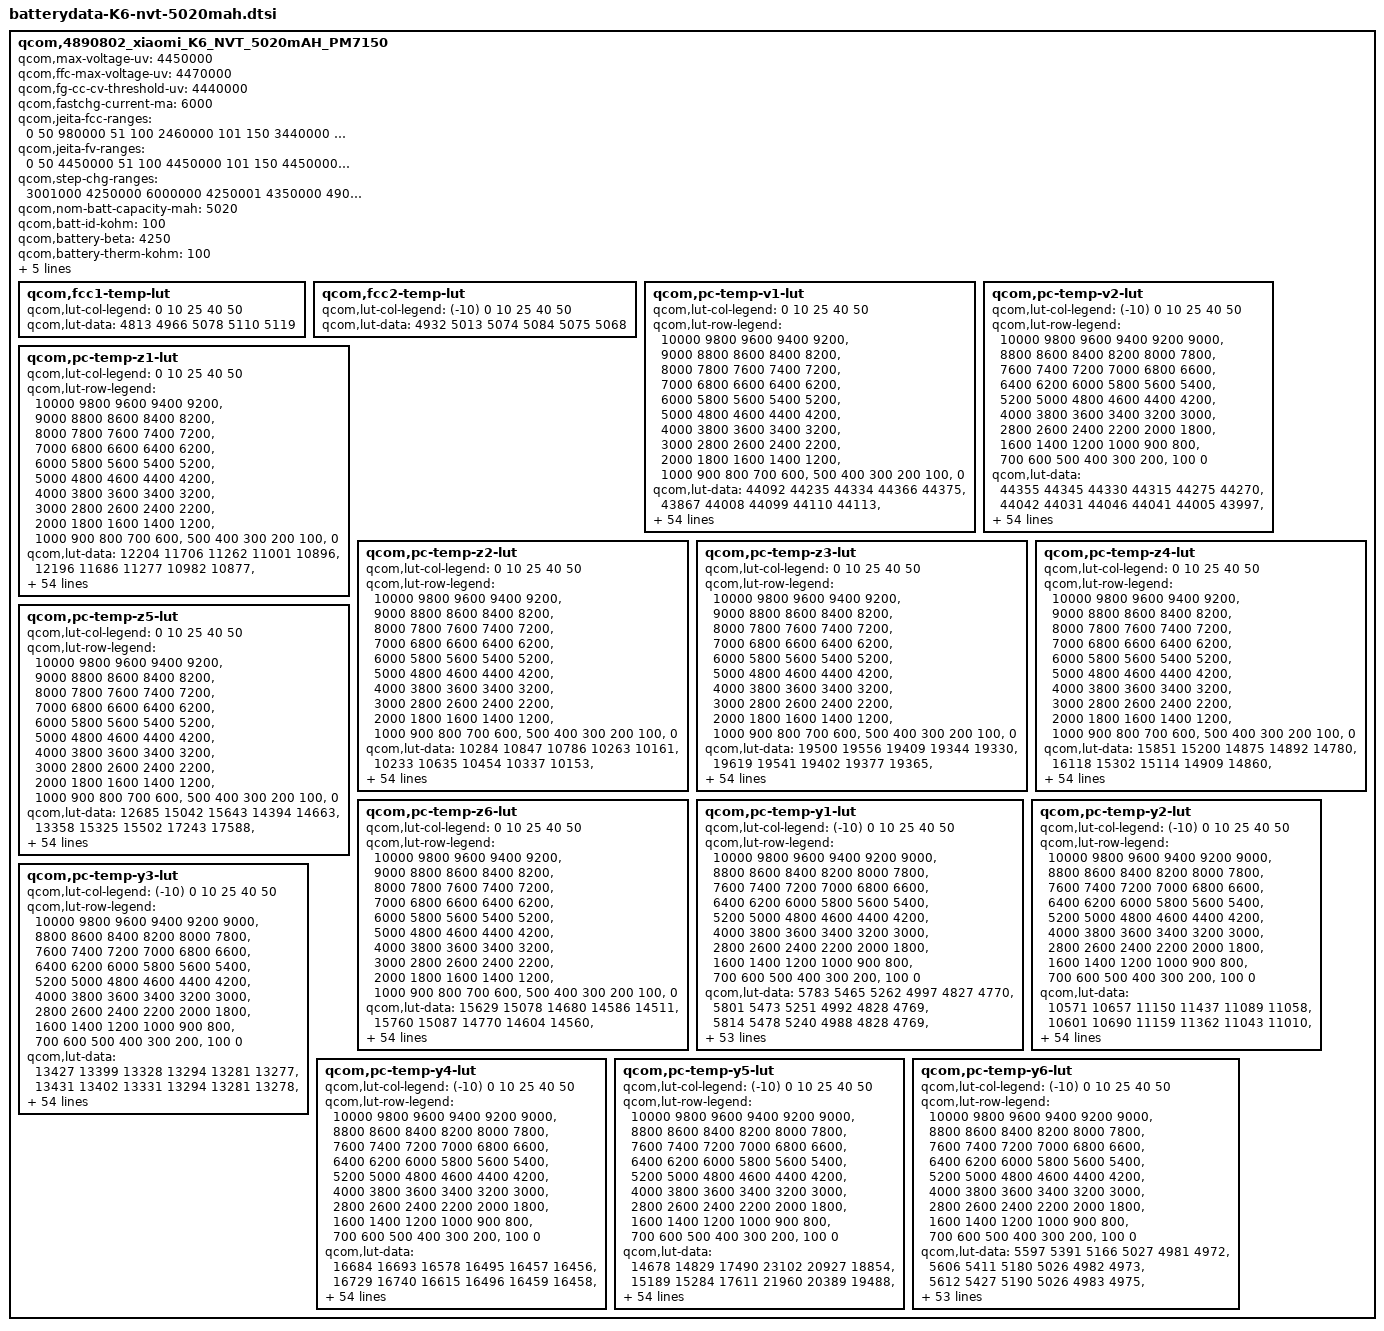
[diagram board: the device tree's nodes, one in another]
/*
 * Copyright (c) 2019, The Linux Foundation. All rights reserved.
 * Copyright (C) 2021 XiaoMi, Inc.
 *
 * This program is free software; you can redistribute it and/or modify
 * it under the terms of the GNU General Public License version 2 and
 * only version 2 as published by the Free Software Foundation.
 *
 * This program is distributed in the hope that it will be useful,
 * but WITHOUT ANY WARRANTY; without even the implied warranty of
 * MERCHANTABILITY or FITNESS FOR A PARTICULAR PURPOSE.  See the
 * GNU General Public License for more details.
 */

qcom,4890802_xiaomi_K6_NVT_5020mAH_PM7150 {
	/*K6_nvt_5020mAH_PM7150_averaged_MasterSlave_Sep20th2020 */
   	qcom,max-voltage-uv = <4450000>;
	qcom,ffc-max-voltage-uv = <4470000>;
	qcom,fg-cc-cv-threshold-uv = <4440000>;
	qcom,fastchg-current-ma = <6000>;
	qcom,jeita-fcc-ranges = <0  50   980000
				51  100  2460000
				101 150  3440000
				151 480  6000000
				481 600  2460000>;
	qcom,jeita-fv-ranges = <0   50  4450000
				51  100  4450000
				101 150  4450000
				151 480  4470000
				481 600  4100000>;
	qcom,step-chg-ranges = <3001000  4250000  6000000
				4250001  4350000  4900000
				4350001  4450000  4900000
				4450001  4460000  3900000
				4460001  4470000  3900000>;
	qcom,nom-batt-capacity-mah = <5020>;
	qcom,batt-id-kohm = <100>;
	qcom,battery-beta = <4250>;
	qcom,battery-therm-kohm = <100>;
	qcom,battery-type = "K6_nvt_5020mah";
	qcom,qg-batt-profile-ver = <100>;
	mi,six-pin-battery;
	mi,use-bq-pump;
	mi,step-chg-hysteresis = <5000>;

	qcom,fcc1-temp-lut {
		qcom,lut-col-legend = <0 10 25 40 50>;
		qcom,lut-data = <4813 4966 5078 5110 5119>;
	};

	qcom,fcc2-temp-lut {
		qcom,lut-col-legend = <(-10) 0 10 25 40 50>;
		qcom,lut-data = <4932 5013 5074 5084 5075 5068>;
	};

	qcom,pc-temp-v1-lut {
		qcom,lut-col-legend = <0 10 25 40 50>;
		qcom,lut-row-legend = <10000 9800 9600 9400 9200>,
			<9000 8800 8600 8400 8200>,
			<8000 7800 7600 7400 7200>,
			<7000 6800 6600 6400 6200>,
			<6000 5800 5600 5400 5200>,
			<5000 4800 4600 4400 4200>,
			<4000 3800 3600 3400 3200>,
			<3000 2800 2600 2400 2200>,
			<2000 1800 1600 1400 1200>,
			<1000 900 800 700 600>,
			<500 400 300 200 100>,
			<0>;
		qcom,lut-data = <44092 44235 44334 44366 44375>,
			<43867 44008 44099 44110 44113>,
			<43638 43781 43882 43894 43895>,
			<43406 43557 43666 43688 43693>,
			<43170 43333 43443 43472 43478>,
			<42930 43099 43216 43251 43257>,
			<42690 42857 42979 43021 43028>,
			<42449 42612 42733 42779 42791>,
			<42209 42368 42485 42531 42549>,
			<41975 42123 42238 42286 42305>,
			<41745 41885 41993 42042 42058>,
			<41521 41651 41753 41801 41816>,
			<41301 41423 41519 41563 41577>,
			<41088 41203 41290 41328 41343>,
			<40879 40988 41067 41103 41117>,
			<40674 40778 40851 40883 40897>,
			<40476 40572 40643 40673 40686>,
			<40283 40376 40443 40470 40482>,
			<40096 40197 40254 40277 40287>,
			<39925 40029 40087 40105 40111>,
			<39775 39856 39917 39938 39943>,
			<39629 39679 39688 39726 39736>,
			<39475 39489 39394 39435 39454>,
			<39316 39246 39165 39188 39207>,
			<39147 38968 39015 39038 39055>,
			<38943 38792 38895 38920 38934>,
			<38739 38703 38788 38801 38813>,
			<38608 38635 38694 38685 38694>,
			<38518 38559 38603 38580 38585>,
			<38449 38486 38508 38485 38488>,
			<38399 38419 38422 38401 38401>,
			<38359 38355 38352 38326 38321>,
			<38321 38297 38292 38259 38247>,
			<38286 38246 38235 38195 38178>,
			<38254 38201 38183 38135 38114>,
			<38223 38161 38133 38077 38051>,
			<38196 38128 38087 38019 37985>,
			<38162 38094 38043 37962 37917>,
			<38110 38039 37982 37891 37836>,
			<38040 37954 37892 37795 37733>,
			<37952 37854 37785 37686 37616>,
			<37830 37733 37670 37574 37497>,
			<37690 37592 37538 37447 37367>,
			<37529 37422 37373 37285 37199>,
			<37373 37267 37217 37138 37059>,
			<37238 37155 37107 37048 36986>,
			<37197 37119 37076 37016 36954>,
			<37173 37097 37052 36994 36933>,
			<37135 37075 37035 36975 36912>,
			<37102 37038 36997 36930 36859>,
			<37051 36871 36796 36701 36615>,
			<36839 36437 36365 36267 36183>,
			<36367 35850 35785 35691 35609>,
			<35725 35026 34987 34907 34828>,
			<34649 33597 33736 33689 33622>,
			<30000 30000 30000 30000 30000>;
	};

	qcom,pc-temp-v2-lut {
		qcom,lut-col-legend = <(-10) 0 10 25 40 50>;
		qcom,lut-row-legend = <10000 9800 9600 9400 9200 9000>,
			<8800 8600 8400 8200 8000 7800>,
			<7600 7400 7200 7000 6800 6600>,
			<6400 6200 6000 5800 5600 5400>,
			<5200 5000 4800 4600 4400 4200>,
			<4000 3800 3600 3400 3200 3000>,
			<2800 2600 2400 2200 2000 1800>,
			<1600 1400 1200 1000 900 800>,
			<700 600 500 400 300 200>,
			<100 0>;
		qcom,lut-data = <44355 44345 44330 44315 44275 44270>,
			<44042 44031 44046 44041 44005 43997>,
			<43757 43746 43781 43781 43749 43741>,
			<43506 43494 43539 43541 43513 43505>,
			<43290 43275 43320 43320 43295 43289>,
			<43075 43055 43096 43094 43072 43069>,
			<42844 42814 42854 42855 42835 42834>,
			<42605 42566 42606 42611 42593 42592>,
			<42364 42317 42357 42365 42349 42349>,
			<42117 42063 42107 42117 42102 42103>,
			<41871 41821 41860 41873 41858 41860>,
			<41633 41600 41619 41631 41619 41621>,
			<41399 41388 41383 41394 41383 41386>,
			<41159 41177 41151 41164 41153 41156>,
			<40914 40966 40926 40940 40928 40931>,
			<40664 40748 40713 40723 40712 40714>,
			<40399 40518 40523 40513 40504 40504>,
			<40124 40275 40331 40309 40304 40303>,
			<39875 40020 40107 40121 40118 40117>,
			<39661 39745 39855 39943 39940 39943>,
			<39463 39490 39610 39740 39745 39753>,
			<39272 39274 39366 39484 39512 39529>,
			<39092 39081 39141 39230 39277 39300>,
			<38921 38899 38954 39025 39068 39092>,
			<38761 38732 38792 38844 38874 38893>,
			<38608 38570 38644 38692 38717 38732>,
			<38455 38400 38508 38565 38591 38604>,
			<38298 38240 38384 38453 38482 38493>,
			<38177 38131 38274 38351 38379 38388>,
			<38097 38053 38173 38257 38284 38291>,
			<38035 37991 38077 38170 38199 38204>,
			<37974 37941 37981 38089 38124 38127>,
			<37917 37899 37902 38013 38052 38054>,
			<37860 37854 37852 37943 37983 37983>,
			<37804 37810 37814 37877 37916 37913>,
			<37748 37763 37773 37808 37837 37827>,
			<37688 37713 37732 37737 37742 37714>,
			<37625 37659 37685 37663 37644 37600>,
			<37555 37594 37625 37586 37553 37504>,
			<37478 37517 37552 37506 37462 37415>,
			<37392 37429 37462 37421 37371 37324>,
			<37304 37325 37343 37328 37281 37234>,
			<37214 37203 37202 37207 37163 37117>,
			<37126 37060 37035 37060 37016 36963>,
			<37043 36917 36876 36927 36898 36847>,
			<36964 36795 36775 36869 36852 36802>,
			<36921 36753 36741 36856 36843 36792>,
			<36874 36721 36707 36836 36830 36778>,
			<36825 36686 36658 36806 36806 36754>,
			<36775 36650 36561 36730 36741 36684>,
			<36718 36587 36342 36481 36468 36393>,
			<36628 36375 35879 35970 35978 35909>,
			<36444 35829 35213 35307 35336 35270>,
			<36058 34987 34182 34372 34446 34386>,
			<35309 33627 32498 32933 33098 33056>,
			<34358 32180 27628 27596 28297 29138>;
	};

	qcom,pc-temp-z1-lut {
		qcom,lut-col-legend = <0 10 25 40 50>;
		qcom,lut-row-legend = <10000 9800 9600 9400 9200>,
			<9000 8800 8600 8400 8200>,
			<8000 7800 7600 7400 7200>,
			<7000 6800 6600 6400 6200>,
			<6000 5800 5600 5400 5200>,
			<5000 4800 4600 4400 4200>,
			<4000 3800 3600 3400 3200>,
			<3000 2800 2600 2400 2200>,
			<2000 1800 1600 1400 1200>,
			<1000 900 800 700 600>,
			<500 400 300 200 100>,
			<0>;
		qcom,lut-data = <12204 11706 11262 11001 10896>,
			<12196 11686 11277 10982 10877>,
			<12184 11668 11252 10970 10870>,
			<12172 11653 11231 10960 10866>,
			<12159 11640 11222 10953 10861>,
			<12148 11629 11215 10946 10856>,
			<12140 11619 11205 10941 10852>,
			<12126 11609 11188 10935 10849>,
			<12109 11597 11176 10931 10847>,
			<12092 11585 11172 10929 10845>,
			<12070 11573 11170 10928 10844>,
			<12054 11559 11169 10927 10843>,
			<12045 11550 11169 10925 10843>,
			<12039 11555 11168 10924 10842>,
			<12033 11564 11167 10924 10843>,
			<12020 11567 11165 10924 10843>,
			<12009 11565 11165 10925 10843>,
			<12010 11564 11165 10925 10845>,
			<12013 11563 11165 10926 10846>,
			<12017 11562 11167 10928 10847>,
			<12045 11562 11170 10930 10848>,
			<12076 11567 11172 10930 10849>,
			<12073 11572 11174 10930 10851>,
			<12047 11574 11176 10930 10854>,
			<12028 11576 11177 10932 10855>,
			<12032 11579 11178 10937 10857>,
			<12041 11582 11182 10941 10859>,
			<12046 11587 11188 10945 10862>,
			<12078 11591 11192 10948 10865>,
			<12107 11597 11193 10951 10867>,
			<12096 11602 11195 10954 10870>,
			<12063 11606 11198 10957 10873>,
			<12055 11609 11204 10960 10876>,
			<12170 11613 11209 10963 10879>,
			<12308 11617 11212 10967 10883>,
			<12301 11621 11215 10971 10886>,
			<12175 11629 11220 10976 10890>,
			<12097 11638 11225 10979 10893>,
			<12107 11647 11231 10983 10896>,
			<12123 11657 11238 10988 10899>,
			<12136 11665 11245 10992 10902>,
			<12148 11672 11250 10995 10906>,
			<12160 11678 11255 10999 10909>,
			<12171 11687 11263 11002 10911>,
			<12194 11687 11270 11006 10914>,
			<12293 11695 11272 11010 10915>,
			<12420 11687 11276 11010 10915>,
			<12184 11694 11279 11009 10915>,
			<12192 11691 11271 11011 10917>,
			<12217 11704 11278 11017 10920>,
			<12236 11722 11294 11022 10925>,
			<12231 11727 11294 11030 10932>,
			<12236 11731 11311 11039 10940>,
			<12246 11787 11323 11053 10953>,
			<12246 11787 11323 11053 10953>,
			<12246 11787 11323 11053 10953>;
	};

	qcom,pc-temp-z2-lut {
		qcom,lut-col-legend = <0 10 25 40 50>;
		qcom,lut-row-legend = <10000 9800 9600 9400 9200>,
			<9000 8800 8600 8400 8200>,
			<8000 7800 7600 7400 7200>,
			<7000 6800 6600 6400 6200>,
			<6000 5800 5600 5400 5200>,
			<5000 4800 4600 4400 4200>,
			<4000 3800 3600 3400 3200>,
			<3000 2800 2600 2400 2200>,
			<2000 1800 1600 1400 1200>,
			<1000 900 800 700 600>,
			<500 400 300 200 100>,
			<0>;
		qcom,lut-data = <10284 10847 10786 10263 10161>,
			<10233 10635 10454 10337 10153>,
			<10288 10501 10514 10333 10154>,
			<10328 10461 10553 10331 10163>,
			<10318 10426 10526 10319 10161>,
			<10296 10391 10466 10284 10142>,
			<10287 10352 10417 10256 10128>,
			<10286 10326 10373 10206 10105>,
			<10285 10313 10349 10161 10078>,
			<10280 10302 10350 10158 10076>,
			<10267 10301 10352 10148 10080>,
			<10255 10315 10354 10140 10086>,
			<10246 10336 10356 10138 10097>,
			<10239 10355 10360 10136 10108>,
			<10239 10377 10374 10141 10118>,
			<10247 10398 10395 10156 10137>,
			<10258 10419 10409 10168 10146>,
			<10270 10439 10420 10179 10151>,
			<10285 10458 10431 10192 10156>,
			<10301 10476 10441 10205 10163>,
			<10318 10492 10453 10223 10178>,
			<10335 10513 10508 10281 10198>,
			<10354 10531 10649 10490 10239>,
			<10373 10546 10713 10627 10271>,
			<10391 10567 10602 10509 10280>,
			<10404 10573 10474 10323 10285>,
			<10416 10556 10464 10310 10283>,
			<10426 10538 10471 10407 10259>,
			<10437 10537 10483 10462 10225>,
			<10445 10538 10535 10400 10157>,
			<10448 10541 10583 10301 10086>,
			<10451 10549 10568 10241 10078>,
			<10454 10561 10520 10192 10090>,
			<10461 10569 10503 10176 10106>,
			<10470 10577 10517 10198 10129>,
			<10475 10584 10539 10235 10161>,
			<10478 10592 10558 10270 10210>,
			<10483 10601 10581 10310 10282>,
			<10494 10616 10613 10347 10334>,
			<10511 10637 10671 10387 10368>,
			<10528 10652 10713 10416 10388>,
			<10547 10658 10702 10426 10389>,
			<10571 10664 10681 10433 10385>,
			<10607 10676 10675 10449 10395>,
			<10882 10796 10701 10455 10400>,
			<10947 10853 10728 10472 10353>,
			<10888 10864 10706 10448 10341>,
			<10742 10939 10676 10450 10369>,
			<10689 11060 10669 10465 10388>,
			<10611 11173 10731 10534 10481>,
			<10241 11165 10724 10488 10377>,
			<10324 11112 10669 10361 10214>,
			<10381 10920 10650 10285 10149>,
			<10169 10591 10585 10235 10098>,
			<10169 10591 10585 10235 10098>,
			<10169 10591 10585 10235 10098>;
	};

	qcom,pc-temp-z3-lut {
		qcom,lut-col-legend = <0 10 25 40 50>;
		qcom,lut-row-legend = <10000 9800 9600 9400 9200>,
			<9000 8800 8600 8400 8200>,
			<8000 7800 7600 7400 7200>,
			<7000 6800 6600 6400 6200>,
			<6000 5800 5600 5400 5200>,
			<5000 4800 4600 4400 4200>,
			<4000 3800 3600 3400 3200>,
			<3000 2800 2600 2400 2200>,
			<2000 1800 1600 1400 1200>,
			<1000 900 800 700 600>,
			<500 400 300 200 100>,
			<0>;
		qcom,lut-data = <19500 19556 19409 19344 19330>,
			<19619 19541 19402 19377 19365>,
			<19696 19536 19428 19386 19375>,
			<19740 19550 19442 19391 19379>,
			<19755 19566 19444 19395 19384>,
			<19765 19569 19446 19398 19391>,
			<19766 19569 19447 19399 19393>,
			<19759 19568 19448 19401 19392>,
			<19749 19565 19449 19403 19390>,
			<19742 19559 19445 19402 19389>,
			<19736 19552 19438 19396 19388>,
			<19730 19543 19432 19392 19387>,
			<19723 19533 19427 19390 19386>,
			<19717 19526 19423 19389 19383>,
			<19711 19519 19419 19387 19381>,
			<19703 19514 19416 19385 19377>,
			<19693 19511 19414 19383 19374>,
			<19679 19507 19411 19381 19371>,
			<19662 19501 19409 19378 19368>,
			<19651 19494 19404 19372 19364>,
			<19645 19492 19400 19365 19358>,
			<19641 19495 19405 19365 19358>,
			<19641 19500 19424 19378 19363>,
			<19643 19505 19433 19387 19368>,
			<19646 19512 19416 19377 19368>,
			<19653 19514 19396 19360 19367>,
			<19662 19504 19395 19364 19370>,
			<19664 19495 19398 19396 19391>,
			<19660 19494 19403 19415 19404>,
			<19654 19495 19420 19411 19399>,
			<19649 19497 19436 19405 19391>,
			<19642 19501 19435 19397 19384>,
			<19637 19506 19428 19389 19379>,
			<19633 19506 19423 19381 19372>,
			<19629 19505 19418 19375 19363>,
			<19625 19504 19414 19370 19354>,
			<19621 19500 19409 19365 19349>,
			<19617 19495 19404 19359 19345>,
			<19612 19490 19401 19358 19344>,
			<19607 19486 19400 19359 19344>,
			<19601 19481 19399 19360 19344>,
			<19592 19478 19396 19359 19347>,
			<19583 19473 19392 19358 19352>,
			<19573 19466 19388 19359 19356>,
			<19498 19440 19380 19359 19356>,
			<19477 19422 19372 19347 19344>,
			<19432 19419 19368 19343 19343>,
			<19308 19391 19364 19340 19331>,
			<19303 19333 19353 19333 19327>,
			<19295 19333 19347 19330 19322>,
			<19273 19331 19352 19342 19333>,
			<19288 19326 19356 19357 19347>,
			<19305 19321 19351 19358 19349>,
			<19326 19346 19350 19353 19350>,
			<19326 19346 19350 19353 19350>,
			<19326 19346 19350 19353 19350>;
	};

	qcom,pc-temp-z4-lut {
		qcom,lut-col-legend = <0 10 25 40 50>;
		qcom,lut-row-legend = <10000 9800 9600 9400 9200>,
			<9000 8800 8600 8400 8200>,
			<8000 7800 7600 7400 7200>,
			<7000 6800 6600 6400 6200>,
			<6000 5800 5600 5400 5200>,
			<5000 4800 4600 4400 4200>,
			<4000 3800 3600 3400 3200>,
			<3000 2800 2600 2400 2200>,
			<2000 1800 1600 1400 1200>,
			<1000 900 800 700 600>,
			<500 400 300 200 100>,
			<0>;
		qcom,lut-data = <15851 15200 14875 14892 14780>,
			<16118 15302 15114 14909 14860>,
			<15930 15325 15038 14882 14845>,
			<15709 15240 14952 14836 14811>,
			<15541 15106 14899 14806 14787>,
			<15385 15013 14854 14782 14767>,
			<15264 14948 14818 14762 14750>,
			<15170 14897 14787 14740 14732>,
			<15092 14857 14763 14723 14718>,
			<15026 14825 14746 14715 14711>,
			<14970 14799 14732 14710 14707>,
			<14923 14775 14724 14706 14704>,
			<14883 14758 14720 14701 14701>,
			<14850 14750 14716 14697 14697>,
			<14821 14745 14711 14692 14694>,
			<14792 14741 14706 14687 14691>,
			<14777 14738 14702 14683 14688>,
			<14778 14736 14699 14679 14685>,
			<14784 14730 14695 14676 14682>,
			<14785 14722 14691 14672 14676>,
			<14770 14719 14688 14669 14670>,
			<14753 14721 14701 14676 14676>,
			<14751 14726 14756 14734 14737>,
			<14752 14758 14796 14780 14784>,
			<14753 14830 14817 14787 14779>,
			<14786 14858 14829 14791 14766>,
			<14835 14847 14824 14782 14747>,
			<14847 14830 14801 14733 14714>,
			<14847 14815 14777 14700 14692>,
			<14846 14799 14750 14695 14688>,
			<14841 14784 14728 14691 14685>,
			<14827 14769 14720 14689 14681>,
			<14814 14757 14716 14686 14677>,
			<14803 14750 14714 14684 14674>,
			<14792 14745 14713 14682 14671>,
			<14780 14741 14712 14681 14670>,
			<14768 14736 14711 14681 14670>,
			<14757 14732 14709 14682 14670>,
			<14745 14729 14709 14684 14671>,
			<14734 14727 14711 14691 14683>,
			<14728 14725 14714 14698 14694>,
			<14724 14716 14709 14695 14690>,
			<14717 14705 14699 14689 14681>,
			<14700 14698 14694 14687 14686>,
			<14695 14679 14679 14679 14681>,
			<14696 14668 14660 14661 14657>,
			<14743 14664 14656 14658 14651>,
			<14878 14683 14649 14649 14647>,
			<14880 14741 14646 14637 14633>,
			<14884 14733 14643 14628 14624>,
			<14901 14737 14651 14647 14654>,
			<14883 14758 14661 14651 14661>,
			<14888 14770 14668 14654 14667>,
			<14891 14757 14672 14661 14667>,
			<14891 14757 14672 14661 14667>,
			<14891 14757 14672 14661 14667>;
	};

	qcom,pc-temp-z5-lut {
		qcom,lut-col-legend = <0 10 25 40 50>;
		qcom,lut-row-legend = <10000 9800 9600 9400 9200>,
			<9000 8800 8600 8400 8200>,
			<8000 7800 7600 7400 7200>,
			<7000 6800 6600 6400 6200>,
			<6000 5800 5600 5400 5200>,
			<5000 4800 4600 4400 4200>,
			<4000 3800 3600 3400 3200>,
			<3000 2800 2600 2400 2200>,
			<2000 1800 1600 1400 1200>,
			<1000 900 800 700 600>,
			<500 400 300 200 100>,
			<0>;
		qcom,lut-data = <12685 15042 15643 14394 14663>,
			<13358 15325 15502 17243 17588>,
			<14059 15683 16925 18187 19154>,
			<14693 16190 17909 19103 20068>,
			<15190 16877 18378 19737 21230>,
			<15623 17514 18706 20171 22540>,
			<16058 18072 19249 20691 23700>,
			<16510 18666 20157 22038 24628>,
			<17018 19361 21051 23495 25465>,
			<17643 20136 21834 23772 26310>,
			<18392 20998 22498 23631 27152>,
			<19234 22044 22704 23798 27987>,
			<20212 22927 22680 24603 28953>,
			<21402 23450 22723 25569 29848>,
			<23006 23881 23114 26421 30512>,
			<25565 24432 23769 27447 31109>,
			<27204 25466 24473 28506 31437>,
			<26656 26251 25316 29937 32731>,
			<25308 26274 26102 30818 33901>,
			<24811 26121 26610 30155 34233>,
			<25743 26442 27217 28898 34826>,
			<27533 31175 31183 29414 34985>,
			<30390 36565 42650 34734 34887>,
			<35648 38665 47789 38404 34684>,
			<41327 40215 36446 31156 29594>,
			<48076 40331 22897 19637 20920>,
			<54210 34389 20818 18784 20289>,
			<54958 28097 20273 24922 26973>,
			<51047 27428 20353 29385 31623>,
			<46370 27325 25290 30798 32192>,
			<42919 27372 31003 31630 32427>,
			<39778 29614 32461 31440 32559>,
			<38104 33034 33139 30424 32938>,
			<37276 35758 34031 29959 32872>,
			<36785 38410 35602 30594 31011>,
			<36672 39544 36718 31282 29007>,
			<36668 39589 36504 31065 28816>,
			<36744 39474 35872 30329 28825>,
			<37967 39181 35536 30067 28790>,
			<39825 38423 35409 30271 28204>,
			<40126 37589 35162 30462 27626>,
			<39002 36757 33584 29288 28071>,
			<38811 35947 31288 27276 29611>,
			<40671 34999 30283 28775 33341>,
			<31818 33172 30870 30364 35120>,
			<27444 30153 31516 26388 28439>,
			<23002 28844 28947 24320 26339>,
			<12393 20001 28519 24354 22026>,
			<12260 14154 24027 24960 24852>,
			<12076 14370 23220 27397 28871>,
			<11731 14217 23760 28236 26766>,
			<12042 13575 21103 26537 23305>,
			<12160 13167 18667 23862 20440>,
			<12675 14088 17777 19307 17859>,
			<12675 14088 17777 19307 17859>,
			<12675 14088 17777 19307 17859>;
	};

	qcom,pc-temp-z6-lut {
		qcom,lut-col-legend = <0 10 25 40 50>;
		qcom,lut-row-legend = <10000 9800 9600 9400 9200>,
			<9000 8800 8600 8400 8200>,
			<8000 7800 7600 7400 7200>,
			<7000 6800 6600 6400 6200>,
			<6000 5800 5600 5400 5200>,
			<5000 4800 4600 4400 4200>,
			<4000 3800 3600 3400 3200>,
			<3000 2800 2600 2400 2200>,
			<2000 1800 1600 1400 1200>,
			<1000 900 800 700 600>,
			<500 400 300 200 100>,
			<0>;
		qcom,lut-data = <15629 15078 14680 14586 14511>,
			<15760 15087 14770 14604 14560>,
			<15687 15085 14745 14594 14555>,
			<15594 15049 14714 14578 14543>,
			<15510 14981 14690 14566 14535>,
			<15423 14932 14668 14556 14530>,
			<15350 14893 14649 14547 14524>,
			<15288 14861 14634 14539 14516>,
			<15235 14834 14621 14532 14509>,
			<15190 14812 14609 14526 14505>,
			<15151 14791 14599 14521 14503>,
			<15118 14772 14591 14516 14500>,
			<15090 14758 14586 14513 14497>,
			<15065 14749 14582 14510 14495>,
			<15043 14743 14577 14506 14492>,
			<15021 14738 14573 14503 14488>,
			<15005 14734 14570 14500 14485>,
			<14997 14730 14567 14497 14482>,
			<14992 14724 14564 14494 14479>,
			<14986 14718 14560 14489 14475>,
			<14979 14716 14557 14484 14469>,
			<14973 14719 14567 14487 14471>,
			<14973 14725 14603 14521 14500>,
			<14977 14744 14620 14544 14522>,
			<14984 14779 14620 14542 14520>,
			<15005 14791 14618 14537 14515>,
			<15031 14784 14615 14534 14512>,
			<15037 14774 14608 14532 14510>,
			<15037 14768 14603 14529 14507>,
			<15037 14763 14602 14525 14503>,
			<15033 14759 14600 14521 14498>,
			<15025 14757 14597 14517 14494>,
			<15019 14755 14593 14511 14489>,
			<15016 14754 14590 14507 14484>,
			<15012 14752 14588 14503 14479>,
			<15009 14751 14586 14500 14473>,
			<15005 14749 14584 14498 14470>,
			<15003 14748 14582 14495 14468>,
			<15004 14749 14582 14495 14468>,
			<15005 14749 14584 14499 14473>,
			<15007 14750 14586 14503 14478>,
			<15012 14749 14584 14502 14478>,
			<15014 14747 14579 14499 14478>,
			<15016 14746 14577 14500 14482>,
			<14996 14733 14570 14497 14480>,
			<14990 14723 14560 14484 14464>,
			<14988 14720 14556 14481 14461>,
			<14984 14716 14552 14475 14454>,
			<14983 14712 14545 14466 14445>,
			<14985 14713 14543 14461 14438>,
			<14988 14719 14552 14476 14457>,
			<14997 14731 14562 14489 14472>,
			<15018 14741 14566 14494 14477>,
			<15047 14763 14574 14498 14481>,
			<15047 14763 14574 14498 14481>,
			<15047 14763 14574 14498 14481>;
	};

	qcom,pc-temp-y1-lut {
		qcom,lut-col-legend = <(-10) 0 10 25 40 50>;
		qcom,lut-row-legend = <10000 9800 9600 9400 9200 9000>,
			<8800 8600 8400 8200 8000 7800>,
			<7600 7400 7200 7000 6800 6600>,
			<6400 6200 6000 5800 5600 5400>,
			<5200 5000 4800 4600 4400 4200>,
			<4000 3800 3600 3400 3200 3000>,
			<2800 2600 2400 2200 2000 1800>,
			<1600 1400 1200 1000 900 800>,
			<700 600 500 400 300 200>,
			<100 0>;
		qcom,lut-data = <5783 5465 5262 4997 4827 4770>,
			<5801 5473 5251 4992 4828 4769>,
			<5814 5478 5240 4988 4828 4769>,
			<5823 5482 5230 4983 4827 4769>,
			<5828 5484 5222 4980 4827 4768>,
			<5830 5486 5219 4977 4826 4768>,
			<5825 5496 5220 4975 4825 4767>,
			<5815 5511 5222 4974 4823 4767>,
			<5811 5511 5221 4973 4821 4766>,
			<5809 5490 5215 4973 4820 4765>,
			<5807 5475 5211 4972 4819 4765>,
			<5806 5473 5213 4969 4818 4764>,
			<5804 5472 5214 4965 4818 4764>,
			<5804 5471 5214 4964 4817 4764>,
			<5806 5471 5214 4963 4817 4764>,
			<5808 5471 5214 4963 4817 4765>,
			<5812 5475 5215 4962 4816 4764>,
			<5817 5480 5216 4961 4816 4764>,
			<5820 5481 5217 4962 4816 4764>,
			<5819 5481 5219 4964 4816 4765>,
			<5817 5481 5220 4965 4817 4766>,
			<5817 5482 5222 4967 4818 4767>,
			<5816 5486 5224 4969 4820 4768>,
			<5815 5490 5225 4972 4821 4770>,
			<5811 5500 5225 4975 4824 4773>,
			<5807 5506 5225 4977 4826 4774>,
			<5810 5499 5224 4978 4828 4775>,
			<5824 5489 5224 4979 4829 4775>,
			<5831 5485 5226 4981 4831 4776>,
			<5821 5483 5230 4985 4832 4779>,
			<5806 5483 5232 4988 4834 4781>,
			<5803 5491 5231 4993 4837 4782>,
			<5808 5506 5230 4996 4840 4784>,
			<5812 5509 5233 4996 4842 4786>,
			<5809 5498 5236 4995 4845 4789>,
			<5802 5489 5238 4996 4847 4791>,
			<5801 5490 5240 5002 4849 4792>,
			<5804 5492 5241 5005 4850 4793>,
			<5806 5493 5240 5004 4851 4794>,
			<5803 5493 5239 5003 4851 4795>,
			<5796 5495 5240 5004 4852 4796>,
			<5796 5495 5245 5008 4853 4797>,
			<5820 5494 5246 5012 4854 4798>,
			<5829 5496 5247 5017 4855 4801>,
			<5802 5500 5253 5024 4861 4804>,
			<5829 5519 5265 5031 4864 4806>,
			<5844 5527 5265 5031 4864 4807>,
			<5862 5538 5273 5031 4865 4807>,
			<5873 5542 5275 5030 4868 4807>,
			<5914 5541 5266 5035 4865 4808>,
			<5896 5546 5289 5035 4866 4810>,
			<5978 5581 5308 5045 4873 4813>,
			<6015 5646 5364 5061 4879 4820>,
			<6091 5674 5407 5081 4888 4828>,
			<6091 5674 5407 5081 4888 4828>,
			<6091 5674 5407 5081 4888 4828>;
	};

	qcom,pc-temp-y2-lut {
		qcom,lut-col-legend = <(-10) 0 10 25 40 50>;
		qcom,lut-row-legend = <10000 9800 9600 9400 9200 9000>,
			<8800 8600 8400 8200 8000 7800>,
			<7600 7400 7200 7000 6800 6600>,
			<6400 6200 6000 5800 5600 5400>,
			<5200 5000 4800 4600 4400 4200>,
			<4000 3800 3600 3400 3200 3000>,
			<2800 2600 2400 2200 2000 1800>,
			<1600 1400 1200 1000 900 800>,
			<700 600 500 400 300 200>,
			<100 0>;
		qcom,lut-data = <10571 10657 11150 11437 11089 11058>,
			<10601 10690 11159 11362 11043 11010>,
			<10650 10743 11156 11287 10992 10955>,
			<10704 10801 11145 11216 10943 10900>,
			<10750 10848 11128 11155 10902 10855>,
			<10775 10867 11107 11111 10875 10827>,
			<10779 10863 11076 11080 10862 10814>,
			<10781 10858 11041 11055 10852 10804>,
			<10788 10860 11016 11032 10840 10788>,
			<10815 10882 10994 11009 10825 10756>,
			<10848 10907 10986 10990 10807 10738>,
			<10870 10924 10995 10973 10780 10746>,
			<10890 10943 11016 10961 10756 10757>,
			<10923 10983 11051 10964 10756 10748>,
			<11007 11089 11112 10983 10769 10722>,
			<11077 11166 11174 11010 10776 10708>,
			<11080 11204 11232 11061 10769 10706>,
			<11075 11241 11286 11133 10763 10707>,
			<11074 11244 11336 11232 10799 10724>,
			<11083 11218 11383 11356 10919 10780>,
			<11094 11199 11398 11397 11012 10840>,
			<11100 11214 11387 11380 11071 10909>,
			<11104 11239 11376 11355 11108 10967>,
			<11106 11242 11381 11328 11101 10992>,
			<11092 11226 11397 11293 11070 11012>,
			<11066 11200 11407 11285 11062 11019>,
			<11041 11159 11416 11329 11095 11022>,
			<11014 11097 11422 11378 11131 11029>,
			<10965 10972 11415 11410 11156 11049>,
			<10526 10632 11396 11448 11194 11090>,
			<9898 10425 11388 11477 11213 11135>,
			<9742 10297 11388 11516 11251 11191>,
			<9722 10054 11387 11540 11299 11235>,
			<9710 9925 11373 11529 11340 11251>,
			<9701 9801 11341 11504 11377 11263>,
			<9693 9719 11300 11485 11383 11261>,
			<9687 9697 11235 11468 11344 11222>,
			<9682 9684 11155 11452 11292 11186>,
			<9678 9676 11067 11432 11235 11177>,
			<9674 9672 10962 11408 11176 11166>,
			<9672 9668 10847 11395 11170 11145>,
			<9670 9665 10716 11378 11204 11081>,
			<9668 9663 10429 11344 11207 11061>,
			<9667 9662 9941 11267 11166 11068>,
			<9665 9660 9774 11205 11114 11014>,
			<9663 9659 9726 11157 11070 10885>,
			<9662 9658 9695 11179 10986 10851>,
			<9661 9658 9678 11171 10993 10860>,
			<9659 9657 9669 11156 11010 10835>,
			<9656 9656 9663 11155 11063 10850>,
			<9652 9654 9658 11076 11002 10837>,
			<9649 9650 9655 10971 10916 10779>,
			<9648 9648 9652 10827 10806 10677>,
			<9647 9648 9651 10641 10671 10545>,
			<9647 9648 9651 10641 10671 10545>,
			<9647 9648 9651 10641 10671 10545>;
	};

	qcom,pc-temp-y3-lut {
		qcom,lut-col-legend = <(-10) 0 10 25 40 50>;
		qcom,lut-row-legend = <10000 9800 9600 9400 9200 9000>,
			<8800 8600 8400 8200 8000 7800>,
			<7600 7400 7200 7000 6800 6600>,
			<6400 6200 6000 5800 5600 5400>,
			<5200 5000 4800 4600 4400 4200>,
			<4000 3800 3600 3400 3200 3000>,
			<2800 2600 2400 2200 2000 1800>,
			<1600 1400 1200 1000 900 800>,
			<700 600 500 400 300 200>,
			<100 0>;
		qcom,lut-data = <13427 13399 13328 13294 13281 13277>,
			<13431 13402 13331 13294 13281 13278>,
			<13437 13407 13334 13294 13281 13279>,
			<13445 13412 13337 13294 13282 13280>,
			<13452 13416 13340 13295 13283 13281>,
			<13455 13418 13342 13295 13283 13282>,
			<13456 13420 13344 13295 13284 13282>,
			<13456 13420 13346 13296 13285 13283>,
			<13456 13420 13347 13297 13286 13283>,
			<13454 13417 13349 13297 13286 13284>,
			<13452 13415 13350 13298 13286 13284>,
			<13458 13422 13351 13298 13286 13285>,
			<13473 13433 13351 13298 13287 13285>,
			<13476 13429 13350 13299 13287 13286>,
			<13443 13398 13345 13302 13287 13286>,
			<13410 13377 13341 13304 13288 13286>,
			<13411 13384 13338 13304 13290 13286>,
			<13419 13395 13336 13305 13292 13286>,
			<13422 13395 13334 13304 13293 13288>,
			<13413 13380 13333 13303 13294 13291>,
			<13401 13366 13330 13302 13294 13292>,
			<13395 13361 13325 13300 13292 13290>,
			<13392 13357 13320 13297 13288 13286>,
			<13389 13352 13317 13293 13285 13283>,
			<13386 13346 13316 13290 13281 13280>,
			<13383 13341 13314 13288 13280 13279>,
			<13375 13338 13312 13288 13280 13279>,
			<13354 13334 13311 13288 13280 13279>,
			<13342 13327 13309 13288 13279 13279>,
			<13347 13306 13308 13289 13279 13278>,
			<13358 13293 13307 13289 13278 13278>,
			<13367 13303 13306 13288 13279 13278>,
			<13377 13323 13305 13288 13279 13278>,
			<13389 13339 13306 13287 13279 13278>,
			<13404 13354 13308 13287 13280 13280>,
			<13421 13372 13310 13287 13280 13280>,
			<13442 13391 13312 13287 13280 13279>,
			<13466 13413 13315 13287 13279 13278>,
			<13494 13444 13318 13287 13279 13278>,
			<13524 13490 13321 13287 13280 13278>,
			<13559 13546 13325 13288 13280 13279>,
			<13597 13612 13329 13290 13282 13280>,
			<13636 13689 13336 13291 13281 13280>,
			<13687 13774 13345 13290 13279 13277>,
			<13755 13881 13366 13290 13278 13276>,
			<13871 13933 13386 13292 13283 13281>,
			<13912 14009 13415 13296 13286 13284>,
			<13972 14105 13451 13300 13289 13286>,
			<14134 14205 13540 13304 13290 13288>,
			<14448 14367 13678 13307 13290 13286>,
			<15515 14771 13926 13306 13286 13284>,
			<19236 16874 14326 13307 13285 13283>,
			<29316 26004 15413 13318 13289 13286>,
			<65535 65535 23721 13338 13296 13295>,
			<65535 65535 23721 13338 13296 13295>,
			<65535 65535 23721 13338 13296 13295>;
	};

	qcom,pc-temp-y4-lut {
		qcom,lut-col-legend = <(-10) 0 10 25 40 50>;
		qcom,lut-row-legend = <10000 9800 9600 9400 9200 9000>,
			<8800 8600 8400 8200 8000 7800>,
			<7600 7400 7200 7000 6800 6600>,
			<6400 6200 6000 5800 5600 5400>,
			<5200 5000 4800 4600 4400 4200>,
			<4000 3800 3600 3400 3200 3000>,
			<2800 2600 2400 2200 2000 1800>,
			<1600 1400 1200 1000 900 800>,
			<700 600 500 400 300 200>,
			<100 0>;
		qcom,lut-data = <16684 16693 16578 16495 16457 16456>,
			<16729 16740 16615 16496 16459 16458>,
			<16791 16811 16653 16498 16460 16460>,
			<16857 16886 16687 16498 16461 16461>,
			<16913 16946 16710 16499 16462 16462>,
			<16944 16971 16719 16499 16462 16462>,
			<16955 16965 16713 16499 16461 16461>,
			<16961 16955 16702 16498 16460 16460>,
			<16962 16952 16693 16498 16460 16460>,
			<16961 16951 16686 16500 16462 16460>,
			<16959 16951 16683 16502 16464 16460>,
			<16943 16952 16685 16507 16467 16460>,
			<16911 16956 16691 16514 16470 16462>,
			<16904 16977 16703 16519 16473 16463>,
			<16959 17063 16729 16524 16478 16466>,
			<17013 17119 16759 16531 16483 16470>,
			<16976 17078 16800 16547 16488 16475>,
			<16861 16992 16834 16568 16496 16481>,
			<16797 16921 16821 16599 16512 16492>,
			<16782 16853 16768 16640 16539 16509>,
			<16771 16800 16715 16650 16549 16516>,
			<16755 16767 16663 16603 16540 16516>,
			<16736 16742 16619 16545 16526 16515>,
			<16715 16716 16597 16514 16503 16503>,
			<16686 16691 16581 16491 16472 16472>,
			<16660 16661 16570 16485 16462 16459>,
			<16650 16608 16561 16484 16462 16458>,
			<16644 16552 16554 16484 16462 16457>,
			<16642 16549 16548 16487 16464 16458>,
			<16657 16589 16542 16492 16470 16462>,
			<16684 16618 16533 16497 16476 16468>,
			<16700 16617 16511 16501 16485 16475>,
			<16710 16615 16496 16504 16492 16484>,
			<16717 16625 16500 16506 16499 16493>,
			<16724 16644 16512 16506 16505 16502>,
			<16729 16664 16527 16505 16505 16503>,
			<16734 16684 16547 16493 16493 16488>,
			<16738 16701 16569 16483 16482 16476>,
			<16740 16705 16589 16481 16476 16476>,
			<16736 16705 16608 16480 16472 16479>,
			<16727 16704 16619 16483 16473 16483>,
			<16722 16700 16624 16494 16480 16493>,
			<16721 16690 16626 16497 16478 16491>,
			<16724 16677 16627 16497 16460 16463>,
			<16743 16663 16624 16490 16445 16442>,
			<16759 16646 16618 16491 16455 16461>,
			<16757 16649 16636 16506 16480 16493>,
			<16750 16660 16680 16526 16514 16530>,
			<16763 16677 16702 16563 16551 16565>,
			<16778 16700 16751 16593 16570 16581>,
			<16854 16728 16801 16584 16500 16493>,
			<17305 16912 16816 16551 16474 16476>,
			<18698 18300 16947 16584 16477 16475>,
			<24018 32152 21389 16634 16486 16474>,
			<24018 32152 21389 16634 16486 16474>,
			<24018 32152 21389 16634 16486 16474>;
	};

	qcom,pc-temp-y5-lut {
		qcom,lut-col-legend = <(-10) 0 10 25 40 50>;
		qcom,lut-row-legend = <10000 9800 9600 9400 9200 9000>,
			<8800 8600 8400 8200 8000 7800>,
			<7600 7400 7200 7000 6800 6600>,
			<6400 6200 6000 5800 5600 5400>,
			<5200 5000 4800 4600 4400 4200>,
			<4000 3800 3600 3400 3200 3000>,
			<2800 2600 2400 2200 2000 1800>,
			<1600 1400 1200 1000 900 800>,
			<700 600 500 400 300 200>,
			<100 0>;
		qcom,lut-data = <14678 14829 17490 23102 20927 18854>,
			<15189 15284 17611 21960 20389 19488>,
			<15683 15746 17728 20708 19891 20101>,
			<16143 16181 17840 19503 19471 20623>,
			<16551 16556 17947 18501 19167 20982>,
			<16890 16836 18050 17860 19013 21109>,
			<17154 17060 18169 17536 19066 21017>,
			<17377 17224 18265 17290 19149 20820>,
			<17585 17186 18229 16942 18886 20543>,
			<17742 16847 17983 16480 18042 20072>,
			<17970 16625 17671 16066 17331 19637>,
			<19184 17336 17316 15494 16899 19256>,
			<21400 18472 16866 14998 16492 18842>,
			<21984 18488 16181 15028 16039 18320>,
			<19677 17294 15202 15287 15541 17514>,
			<17406 16492 14832 15388 15356 16805>,
			<18613 19099 15950 15023 15494 16129>,
			<22330 23284 17772 14632 15667 15638>,
			<23864 23869 19535 14872 15621 15653>,
			<22625 22296 21467 15898 15374 15907>,
			<21223 21221 22327 17384 15503 16369>,
			<21194 21684 22528 20688 18708 18725>,
			<21682 22534 22622 23352 21945 21122>,
			<22182 22956 22808 22711 21672 21362>,
			<22681 23193 23274 20891 20329 21286>,
			<23079 23352 23459 20271 19561 21107>,
			<22043 22964 23245 20269 19198 20663>,
			<17245 21848 23071 20301 18866 20031>,
			<13949 20123 23575 20586 18266 19145>,
			<13397 15827 24616 21138 17297 18007>,
			<13090 13253 24862 21410 17006 17514>,
			<13050 13550 23886 21595 17204 17362>,
			<13094 14076 22741 21860 17556 17292>,
			<13169 14212 22136 22539 18390 18067>,
			<13361 14256 21650 23492 19826 19933>,
			<13674 14321 21054 23935 21025 20901>,
			<13928 14458 20213 24159 22111 21255>,
			<14181 14656 19632 24123 22886 21547>,
			<14327 14887 19392 23075 23297 22020>,
			<14313 15224 19156 21625 23571 22566>,
			<14258 15419 19000 21344 23582 22799>,
			<14135 15318 18901 21453 23338 22885>,
			<13631 15078 18380 20952 23093 23073>,
			<13249 14669 16823 19714 22532 23728>,
			<12840 14480 15571 18911 19341 19901>,
			<12970 13990 14836 19310 19758 18798>,
			<12983 14029 14701 19748 18779 16966>,
			<13045 14142 14068 19061 17619 15705>,
			<13163 14003 14590 18634 16642 15233>,
			<13352 14092 14463 18325 16318 14811>,
			<12992 14253 14348 18220 16462 16344>,
			<11118 12338 13839 18979 17351 15927>,
			<9813 9876 12878 18569 18159 16082>,
			<9282 9134 9536 18321 20902 20007>,
			<9282 9134 9536 18321 20902 20007>,
			<9282 9134 9536 18321 20902 20007>;
	};

	qcom,pc-temp-y6-lut {
		qcom,lut-col-legend = <(-10) 0 10 25 40 50>;
		qcom,lut-row-legend = <10000 9800 9600 9400 9200 9000>,
			<8800 8600 8400 8200 8000 7800>,
			<7600 7400 7200 7000 6800 6600>,
			<6400 6200 6000 5800 5600 5400>,
			<5200 5000 4800 4600 4400 4200>,
			<4000 3800 3600 3400 3200 3000>,
			<2800 2600 2400 2200 2000 1800>,
			<1600 1400 1200 1000 900 800>,
			<700 600 500 400 300 200>,
			<100 0>;
		qcom,lut-data = <5597 5391 5166 5027 4981 4972>,
			<5606 5411 5180 5026 4982 4973>,
			<5612 5427 5190 5026 4983 4975>,
			<5616 5439 5196 5026 4983 4976>,
			<5619 5447 5199 5025 4984 4977>,
			<5620 5450 5199 5025 4984 4977>,
			<5619 5446 5197 5025 4985 4978>,
			<5616 5440 5191 5025 4985 4978>,
			<5612 5434 5187 5025 4986 4978>,
			<5607 5428 5183 5025 4986 4978>,
			<5603 5425 5182 5026 4987 4979>,
			<5601 5428 5182 5027 4988 4979>,
			<5599 5432 5182 5028 4989 4980>,
			<5598 5436 5182 5031 4990 4981>,
			<5594 5440 5185 5034 4992 4982>,
			<5588 5442 5189 5038 4993 4983>,
			<5577 5436 5198 5042 4996 4985>,
			<5558 5422 5207 5048 5000 4987>,
			<5545 5404 5203 5056 5005 4991>,
			<5538 5376 5186 5067 5014 4998>,
			<5532 5354 5169 5069 5016 5001>,
			<5528 5345 5151 5054 5012 4999>,
			<5525 5339 5136 5036 5005 4996>,
			<5523 5333 5129 5024 4996 4989>,
			<5522 5328 5125 5016 4985 4978>,
			<5521 5322 5122 5013 4981 4974>,
			<5519 5313 5120 5013 4981 4974>,
			<5516 5305 5119 5014 4981 4974>,
			<5515 5304 5118 5015 4982 4974>,
			<5524 5315 5118 5017 4983 4975>,
			<5542 5330 5117 5019 4985 4976>,
			<5561 5350 5114 5021 4987 4979>,
			<5582 5377 5112 5022 4990 4981>,
			<5605 5407 5115 5023 4993 4985>,
			<5630 5442 5125 5024 4995 4988>,
			<5658 5481 5137 5024 4995 4988>,
			<5689 5525 5151 5021 4992 4984>,
			<5721 5575 5169 5019 4988 4980>,
			<5755 5627 5190 5019 4987 4980>,
			<5789 5684 5214 5020 4986 4981>,
			<5822 5745 5242 5021 4987 4983>,
			<5860 5809 5272 5028 4990 4987>,
			<5901 5879 5306 5031 4990 4986>,
			<5952 5955 5345 5032 4983 4976>,
			<6020 6048 5393 5033 4978 4970>,
			<6128 6098 5431 5036 4986 4980>,
			<6172 6163 5491 5045 4995 4991>,
			<6235 6248 5569 5055 5007 5003>,
			<6387 6344 5682 5069 5018 5015>,
			<6677 6494 5840 5080 5024 5019>,
			<7628 6853 6088 5079 5001 4992>,
			<10633 8573 6444 5074 4994 4987>,
			<18112 15475 7378 5105 4999 4990>,
			<45554 57048 14280 5156 5008 4997>,
			<45554 57048 14280 5156 5008 4997>,
			<45554 57048 14280 5156 5008 4997>;
	};

};
